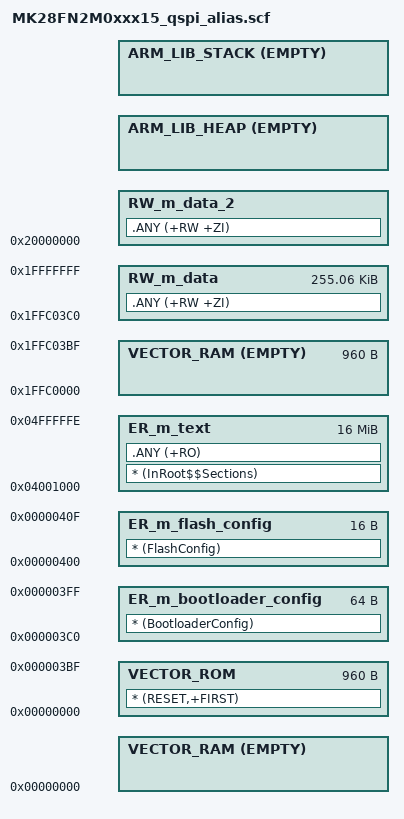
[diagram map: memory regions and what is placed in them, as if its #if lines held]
#! armcc -E
/*
** ###################################################################
**     Processors:          MK28FN2M0CAU15R
**                          MK28FN2M0VMI15
**
**     Compiler:            Keil ARM C/C++ Compiler
**     Reference manual:    K28P210M150SF5RM, Rev. 1, Sep 2016
**     Version:             rev. 1.1, 2016-10-20
**     Build:               b170313
**
**     Abstract:
**         Linker file for the Keil ARM C/C++ Compiler
**
**     The Clear BSD License
**     Copyright 2016 Freescale Semiconductor, Inc.
**     Copyright 2016-2017 NXP
**     All rights reserved.
**     
**     Redistribution and use in source and binary forms, with or without modification,
**     are permitted (subject to the limitations in the disclaimer below) provided
**      that the following conditions are met:
**
**     o Redistributions of source code must retain the above copyright notice, this list
**       of conditions and the following disclaimer.
**
**     o Redistributions in binary form must reproduce the above copyright notice, this
**       list of conditions and the following disclaimer in the documentation and/or
**       other materials provided with the distribution.
**
**     o Neither the name of the copyright holder nor the names of its
**       contributors may be used to endorse or promote products derived from this
**       software without specific prior written permission.
**
**     NO EXPRESS OR IMPLIED LICENSES TO ANY PARTY'S PATENT RIGHTS ARE GRANTED BY THIS LICENSE.
**     THIS SOFTWARE IS PROVIDED BY THE COPYRIGHT HOLDERS AND CONTRIBUTORS "AS IS" AND
**     ANY EXPRESS OR IMPLIED WARRANTIES, INCLUDING, BUT NOT LIMITED TO, THE IMPLIED
**     WARRANTIES OF MERCHANTABILITY AND FITNESS FOR A PARTICULAR PURPOSE ARE
**     DISCLAIMED. IN NO EVENT SHALL THE COPYRIGHT HOLDER OR CONTRIBUTORS BE LIABLE FOR
**     ANY DIRECT, INDIRECT, INCIDENTAL, SPECIAL, EXEMPLARY, OR CONSEQUENTIAL DAMAGES
**     (INCLUDING, BUT NOT LIMITED TO, PROCUREMENT OF SUBSTITUTE GOODS OR SERVICES;
**     LOSS OF USE, DATA, OR PROFITS; OR BUSINESS INTERRUPTION) HOWEVER CAUSED AND ON
**     ANY THEORY OF LIABILITY, WHETHER IN CONTRACT, STRICT LIABILITY, OR TORT
**     (INCLUDING NEGLIGENCE OR OTHERWISE) ARISING IN ANY WAY OUT OF THE USE OF THIS
**     SOFTWARE, EVEN IF ADVISED OF THE POSSIBILITY OF SUCH DAMAGE.
**
**     http:                 www.nxp.com
**     mail:                 support@nxp.com
**
** ###################################################################
*/

#if (defined(__ram_vector_table__))
  #define __ram_vector_table_size__    0x000003C0
#else
  #define __ram_vector_table_size__    0x00000000
#endif

#define m_interrupts_start             0x00000000
#define m_interrupts_size              0x000003C0

#define m_bootloader_config_start      0x000003C0
#define m_bootloader_config_size       0x00000040

#define m_flash_config_start           0x00000400
#define m_flash_config_size            0x00000010

#define m_text_start                   0x04001000
#define m_text_size                    0x00FFEFFF

#define m_interrupts_ram_start         0x1FFC0000
#define m_interrupts_ram_size          __ram_vector_table_size__

#define m_data_start                   (m_interrupts_ram_start + m_interrupts_ram_size)
#define m_data_size                    (0x00040000 - m_interrupts_ram_size)

#define m_data_2_start                 0x20000000
#define m_data_2_size                  0x00040000

/* Sizes */
#if (defined(__stack_size__))
  #define Stack_Size                   __stack_size__
#else
  #define Stack_Size                   0x0400
#endif

#if (defined(__heap_size__))
  #define Heap_Size                    __heap_size__
#else
  #define Heap_Size                    0x0400
#endif

LR_m_text m_text_start m_text_size {   ; load region size_region
  ER_m_text m_text_start m_text_size { ; load address = execution address
    * (InRoot$$Sections)
    .ANY (+RO)
  }
  RW_m_data m_data_start m_data_size { ; RW data
    .ANY (+RW +ZI)
  }
  RW_m_data_2 m_data_2_start m_data_2_size-Stack_Size-Heap_Size { ; RW data
    .ANY (+RW +ZI)
  }
  ARM_LIB_HEAP ((ImageLimit(RW_m_data_2) == m_data_2_start) ? ImageLimit(RW_m_data) : +0) EMPTY Heap_Size { ; Heap region growing up
  }
  ARM_LIB_STACK m_data_2_start+m_data_2_size EMPTY -Stack_Size { ; Stack region growing down
  }
}

LR_m_interrupts m_interrupts_start m_interrupts_size {
#if (!defined(__ram_vector_table__))
  VECTOR_RAM m_interrupts_start EMPTY 0 {
  }
#endif
  VECTOR_ROM m_interrupts_start m_interrupts_size { ; load address = execution address
    * (RESET,+FIRST)
  }
}

LR_m_bootloader_config m_bootloader_config_start m_bootloader_config_size {
  ER_m_bootloader_config m_bootloader_config_start m_bootloader_config_size { ; load address = execution address
    * (BootloaderConfig)
  }
}

LR_m_flash_config m_flash_config_start m_flash_config_size {
  ER_m_flash_config m_flash_config_start m_flash_config_size { ; load address = execution address
    * (FlashConfig)
  }
}

#if (defined(__ram_vector_table__))
LR_m_interrupts_ram m_interrupts_ram_start m_interrupts_ram_size {
  VECTOR_RAM m_interrupts_ram_start EMPTY m_interrupts_ram_size {
  }
}
#endif

